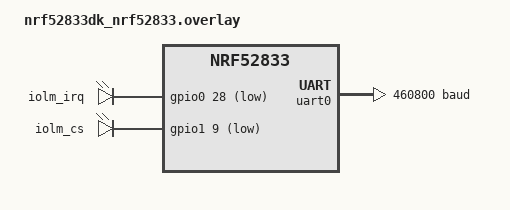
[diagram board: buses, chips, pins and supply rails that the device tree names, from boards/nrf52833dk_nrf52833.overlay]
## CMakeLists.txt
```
# Copyright (c) 2024 Victor Chavez
# SPDX-License-Identifier: GPL-3.0-or-later

cmake_minimum_required(VERSION 3.20.0)
set(IOLINK_MODULE ${CMAKE_CURRENT_SOURCE_DIR}/../..)
set(ZEPHYR_EXTRA_MODULES ${IOLINK_MODULE})
find_package(Zephyr REQUIRED HINTS $ENV{ZEPHYR_BASE})
project(ifm_sample_app)

target_sources(app PRIVATE src/iolink_smi.c
                            src/iolink_handler.c
                            src/iol_master_sample_app.c
)
```

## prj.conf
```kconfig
CONFIG_CPP=y
CONFIG_STD_CPP17=y
CONFIG_THREAD_NAME=y
CONFIG_LOG=y
CONFIG_IOLINK=y
CONFIG_IOLINK_LOG_LEVEL_DBG=y
CONFIG_ASSERT=y
CONFIG_MINIMAL_LIBC=y
CONFIG_MINIMAL_LIBC_MALLOC_ARENA_SIZE=32768
CONFIG_LOG_BUFFER_SIZE=16384
```

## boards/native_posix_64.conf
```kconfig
CONFIG_SPI_EMUL=y
CONFIG_EMUL=y
CONFIG_GPIO_EMUL=y
```

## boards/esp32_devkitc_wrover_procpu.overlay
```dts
/ {

	iolm_gpios: iolm_gpios {
		compatible = "gpio-leds";
		iolm_irq: iolm_irq {
			status = "okay";
			gpios = <&gpio0 18 (GPIO_ACTIVE_LOW)>;
			label = "iolm_irq";
		};
		iolm_cs: iolm_cs {
			status = "okay";
			gpios = <&gpio0 19 (GPIO_ACTIVE_LOW)>;
			label = "iolm_cs";
		};
	};
    
	aliases {
		iolm-spi= &spi2;
        iolm-cs = &iolm_cs;
        iolm-irq = &iolm_irq;
	};

};

&uart0 {
	current-speed = <460800>;
};
```

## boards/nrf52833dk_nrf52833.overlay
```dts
/ {

	iolm_gpios: iolm_gpios {
		compatible = "gpio-leds";
		iolm_irq: iolm_irq {
			status = "okay";
			gpios = <&gpio0 28 (GPIO_ACTIVE_LOW)>;
			label = "iolm_irq";
		};
		iolm_cs: iolm_cs {
			status = "okay";
			gpios = <&gpio1 9 (GPIO_ACTIVE_LOW)>;
			label = "iolm_cs";
		};
	};
    
	aliases {
		iolm-spi= &spi1;
        iolm-cs = &iolm_cs;
        iolm-irq = &iolm_irq;
	};

};

&uart0 {
	current-speed = <460800>;
};

&pinctrl {

	spi1_default: spi1_default {
		group1 {
			psels = <NRF_PSEL(SPIM_SCK, 0, 31)>,
				<NRF_PSEL(SPIM_MOSI, 0, 30)>,
				<NRF_PSEL(SPIM_MISO, 0,29)>;
		};
	};

	spi1_sleep: spi1_sleep {
		group1 {
			psels = <NRF_PSEL(SPIM_SCK, 0, 31)>,
				<NRF_PSEL(SPIM_MOSI, 0, 30)>,
				<NRF_PSEL(SPIM_MISO, 0, 29)>;
			low-power-enable;
		};
	};
};
```

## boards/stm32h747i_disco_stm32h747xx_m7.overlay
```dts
&gpioe {
    status="okay";
};
```

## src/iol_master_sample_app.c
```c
/*********************************************************************
 *        _       _         _
 *  _ __ | |_  _ | |  __ _ | |__   ___
 * | '__|| __|(_)| | / _` || '_ \ / __|
 * | |   | |_  _ | || (_| || |_) |\__ \
 * |_|    \__|(_)|_| \__,_||_.__/ |___/
 *
 * www.rt-labs.com
 * Copyright 2021 rt-labs AB, Sweden.
 *
 * This software is dual-licensed under GPLv3 and a commercial
 * license. See the file LICENSE.md distributed with this software for
 * full license information.
 ********************************************************************/

#include <stdio.h>
#include "osal.h"
#include "osal_irq.h"
#include "osal_log.h"
#include "iolink.h"
#include "iolink_max14819.h"
#include "iolink_handler.h"
#include <iolm/zephyr.h>

static const struct device *const spi_dev = DEVICE_DT_GET(DT_ALIAS(iolm_spi));
static const struct gpio_dt_spec irq_dev = GPIO_DT_SPEC_GET(DT_ALIAS(iolm_irq), gpios);

#define IOLINK_HANDLER_THREAD_STACK_SIZE (8192)
#define IOLINK_HANDLER_THREAD_PRIO       5
static K_THREAD_STACK_DEFINE(iolm_handler_stack, IOLINK_HANDLER_THREAD_STACK_SIZE); 


#define IOLINK_APP_CHIP0_IRQ      25

#define IOLINK_APP_CHIP0_ADDRESS 0x0

#ifndef IOLINK_APP_CHIP1_ADDRESS
#define IOLINK_APP_CHIP1_ADDRESS 0x0
#endif


static iolink_pl_mode_t mode_ch[] =
{
   iolink_mode_SDCI,
   iolink_mode_INACTIVE,
#ifdef IOLINK_APP_CHIP1_SPI
   iolink_mode_SDCI,
   iolink_mode_INACTIVE,
#endif
};

void main_handler_thread (void * ctx)
{
   const iolink_m_cfg_t * cfg = (const iolink_m_cfg_t *)ctx;
   iolink_handler (*cfg);
}

static iolink_hw_drv_t * main_14819_init(const char* name, const iolink_14819_cfg_t * cfg,
                                          const struct device * gpio_port,int irq_pin)
{
   iolink_hw_drv_t  * drv;
   drv = iolink_14819_init (cfg);
   if (drv == NULL)
   {
      LOG_ERR ("APP: Failed to open SPI %s\n", name);
      return NULL;
   }
   if (_iolink_setup_int_zephyr (gpio_port, irq_pin, iolink_14819_isr, drv) < 0)
   {
      LOG_ERR ("APP: Failed to setup interrupt %s\n", name);
      return NULL;
   }
   return drv;
}

static iolink_m_cfg_t iolink_cfg = {
   .cb_arg                   = NULL,
   .cb_smi                   = NULL,
   .cb_pd                    = NULL,
   /* Not needed, statically set with Kconfig*/
   .master_thread_prio       = 0,
   .master_thread_stack_size = 0,
   .dl_thread_prio           = 0,
   .dl_thread_stack_size     = 0,
};

os_thread_t * iolink_handler_thread;
iolink_hw_drv_t * hw[2];
#define CURR_100MA 0x00
#define CURR_200MA 0x01
#define CURR_300MA 0x02
#define CURR_500MA 0x03
#define DRVRCURRLIM_CLDIS BIT(5)

#define CURR_OFF 0x06

#define CL_CONF(x)  ((x) << CURR_OFF)
static const iolink_14819_cfg_t iol_14819_0_cfg = {
      .chip_address   = IOLINK_APP_CHIP0_ADDRESS,
      .spi_slave_name = spi_dev,
      .CQCfgA         = MAX14819_CQCFG_DRVDIS | MAX14819_CQCFG_SINKSEL(0x2),
      .CQCfgB         = MAX14819_CQCFG_DRVDIS | MAX14819_CQCFG_SINKSEL(0x2),
      .LPCnfgA        = MAX14819_LPCNFG_LPEN,
      .LPCnfgB        = MAX14819_LPCNFG_LPEN,
      .IOStCfgA       = MAX14819_IOSTCFG_DICSINK | MAX14819_IOSTCFG_DIEC3TH,
      .IOStCfgB       = MAX14819_IOSTCFG_DICSINK | MAX14819_IOSTCFG_DIEC3TH,
      .DrvCurrLim     = CL_CONF(CURR_300MA),
      .Clock          = MAX14819_CLOCK_XTALEN | MAX14819_CLOCK_TXTXENDIS,
};

#ifdef IOLINK_APP_CHIP1_SPI

static const iolink_14819_cfg_t iol_14819_1_cfg = {
      .chip_address   = IOLINK_APP_CHIP1_ADDRESS,
      .spi_slave_name = IOLINK_APP_CHIP1_SPI,
      .CQCfgA         = MAX14819_CQCFG_DRVDIS | MAX14819_CQCFG_SINKSEL(0x2),
      .LPCnfgA        = MAX14819_LPCNFG_LPEN,
      .IOStCfgA       = MAX14819_IOSTCFG_DICSINK | MAX14819_IOSTCFG_DIEC3TH,
      .DrvCurrLim     = 0x00,
      .Clock          = MAX14819_CLOCK_XTALEN | MAX14819_CLOCK_TXTXENDIS,
};
#endif

iolink_port_cfg_t port_cfgs[] = {
      {
         .name = "/iolink0/0",
         .mode = &mode_ch[0],
         .arg  = (void*)0,
      },
      {
         .name = "/iolink0/1",
         .mode = &mode_ch[0],
         .arg  = (void*)1,
      },
#ifdef IOLINK_APP_CHIP1_SPI
      {
         .name = "/iolink1/0",
         .mode = &mode_ch[2],
         .drv  = hw[1],
         .arg  = (void*)0,
      },
      {
         .name = "/iolink1/1",
         .mode = &mode_ch[3],
         .drv  = hw[1],
         .arg  = (void*)1,
      },
#endif
   };

int main(void)
{


   LOG_INF("Starting app");
   hw[0] = main_14819_init("/iolink0", &iol_14819_0_cfg, irq_dev.port, irq_dev.pin);
   if (hw[0] == NULL) {
      return 0;
   }
#ifdef IOLINK_APP_CHIP1_SPI
   hw[1] = main_14819_init("/iolink1", &iol_14819_1_cfg, irq_dev.port, irq_dev.pin);
#endif
   port_cfgs[0].drv = hw[0];
   port_cfgs[1].drv = hw[0];


   iolink_cfg.port_cnt  = NELEMENTS (port_cfgs);
   iolink_cfg.port_cfgs = port_cfgs;
   LOG_INF("Total port cfg %d",iolink_cfg.port_cnt);

   k_sleep(K_MSEC(200));


   iolink_handler_thread = os_thread_create (
      "iolink_handler_thread",
      IOLINK_HANDLER_THREAD_PRIO,
      iolm_handler_stack,
      K_THREAD_STACK_SIZEOF(iolm_handler_stack),
      main_handler_thread,
      (void*)&iolink_cfg);
   CC_ASSERT (iolink_handler_thread != NULL);
   return 0;
}
```

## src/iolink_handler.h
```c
/*********************************************************************
 *        _       _         _
 *  _ __ | |_  _ | |  __ _ | |__   ___
 * | '__|| __|(_)| | / _` || '_ \ / __|
 * | |   | |_  _ | || (_| || |_) |\__ \
 * |_|    \__|(_)|_| \__,_||_.__/ |___/
 *
 * www.rt-labs.com
 * Copyright 2021 rt-labs AB, Sweden.
 *
 * This software is dual-licensed under GPLv3 and a commercial
 * license. See the file LICENSE.md distributed with this software for
 * full license information.
 ********************************************************************/

#ifndef IOLINK_HANDLER_H
#define IOLINK_HANDLER_H

#include "sys/osal_sys.h"
#include "iolink.h"

#define MASTER_VENDOR_ID 1171
#define MASTER_ID        123

typedef enum
{
   NONE,
   IFM_LAMP,
   IFM_RFID,
   IFM_SENS,
   IFM_HMI,
   GOLDEN,
   UNKNOWN,
} iolink_device_type_t;

/* Port events for app_port.event */
typedef enum
{
   SMI_READ_CNF          = 0x01,
   SMI_WRITE_CNF         = 0x02,
   SMI_PORTCFG_CNF       = 0x04,
   SMI_PORTSTATUS_CNF    = 0x08,
   SMI_MASTERIDENT_CNF   = 0x10,
   SMI_PARSERV_TO_DS_CNF = 0x20,
   SMI_PDIN_CNF = 0x40
} iolink_app_port_event_t;

typedef enum
{
   IOL_STATE_INACTIVE = 0,
   IOL_STATE_STARTING,
   IOL_STATE_STOPPING,
   IOL_STATE_RUNNING,
   IOL_STATE_WU_RETRY_WAIT_TSD,
} iolink_app_port_state_t;

typedef struct iolink_app_portstatus
{
   iolink_port_status_info_t port_status_info;
   iolink_port_quality_info_t port_quality_info;
   uint8_t revision_id;
   iolink_transmission_rate_t transmission_rate;
   uint8_t master_cycle_time;
   uint16_t vendorid;
   uint32_t deviceid;
} iolink_app_port_status_t;

#define PORT_EVENT_COUNT 10

typedef struct iolink_app_master_ctx iolink_app_master_ctx_t;
typedef struct iolink_app_port_ctx iolink_app_port_ctx_t;

typedef struct iolink_app_port_ctx
{
   iolink_app_master_ctx_t * app_master;
   uint8_t portnumber;
   iolink_device_type_t type;
   os_event_t * event;
   uint8_t allocated;
   iolink_app_port_state_t app_port_state;
   iolink_app_port_status_t status;
   os_mutex_t * status_mtx;
   iolink_smi_errortypes_t errortype;
   uint32_t last_pdin_print;

   struct
   {
      uint8_t count;
      diag_entry_t diag_entry[PORT_EVENT_COUNT];
      iolink_eventcode_t eventcode[PORT_EVENT_COUNT];
   } events;
   os_mutex_t * event_mtx;
   struct
   {
      iolink_port_qualifier_info_t pqi;
      uint8_t data[IOLINK_PD_MAX_SIZE];
      uint8_t data_len;
   } pdin;
   struct
   {
      uint16_t data_len;
   } param_read;
   os_mutex_t * pdout_mtx;
   void (*run_function) (iolink_app_port_ctx_t * app_port);
#ifdef __rtk__
   bool alarm_active;
#endif
} iolink_app_port_ctx_t;

typedef struct iolink_app_master_ctx
{
   iolink_m_t * master;
   iolink_app_port_ctx_t app_port[IOLINK_NUM_PORTS];
   os_event_t * app_event;
   uint16_t vendorid;
   uint32_t masterid;
} iolink_app_master_ctx_t;

extern iolink_app_master_ctx_t iolink_app_master;

void iolink_handler (iolink_m_cfg_t m_cfg);

iolink_smi_errortypes_t wait_for_cnf (
   iolink_app_port_ctx_t * app_port,
   uint32_t mask,
   uint32_t ms);

uint8_t get_port_status (iolink_app_port_ctx_t * app_port);

#endif // IOLINK_HANDLER_H
```

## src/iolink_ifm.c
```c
/*********************************************************************
 *        _       _         _
 *  _ __ | |_  _ | |  __ _ | |__   ___
 * | '__|| __|(_)| | / _` || '_ \ / __|
 * | |   | |_  _ | || (_| || |_) |\__ \
 * |_|    \__|(_)|_| \__,_||_.__/ |___/
 *
 * www.rt-labs.com
 * Copyright 2021 rt-labs AB, Sweden.
 *
 * This software is dual-licensed under GPLv3 and a commercial
 * license. See the file LICENSE.md distributed with this software for
 * full license information.
 ********************************************************************/

#include <stdio.h>
#include <string.h>
#include <strings.h>
#include "osal.h"
#include "osal_log.h"
#include "iolink.h"
#include "iolink_handler.h"
#include "iolink_smi.h"

#define RFID_DATA_SIZE 8

static bool ifmrfid_get_tag_present (uint8_t * data)
{
   return (data[1] & 0x04);
}

static uint8_t ifmrfid_get_error_code (uint8_t * data)
{
   return data[31];
}

static bool is_all_zeroes (uint8_t * data, int length)
{
   int i;

   for (i = 0; i < length; i++)
   {
      if (data[i] != 0)
      {
         return false;
      }
   }

   return true;
}

static void ifmrfid_run (iolink_app_port_ctx_t * app_port)
{
   uint8_t port_index = app_port->portnumber - 1;
   uint8_t pdata[IOLINK_PD_MAX_SIZE];
   static bool tag_is_present[IOLINK_NUM_PORTS] = {false};

   if (do_smi_pdin (app_port, NULL, pdata) != IOLINK_PD_MAX_SIZE)
   {
      LOG_WRN (
         "%s: Failed to get PDIn (RFID port #%u)\n",
         __func__,
         app_port->portnumber);
      return;
   }

   uint8_t error_code = ifmrfid_get_error_code (pdata);
   if (error_code != 0)
   {
      LOG_ERR (
         "%s: Got error code %d (RFID port #%u)\n",
         __func__,
         error_code,
         app_port->portnumber);
      return;
   }

   if (ifmrfid_get_tag_present (pdata))
   {
      if (!tag_is_present[port_index]) // tagPresent transition from 0 to 1
      {
         // check if UID is invalid, i.e. all zeroes (data starts at byte 2)
         if (is_all_zeroes (&pdata[2], RFID_DATA_SIZE))
         {
            LOG_ERR (
               "%s: Got tag_present with UID = 0 (RFID port #%u)\n",
               __func__,
               app_port->portnumber);
            return;
         }

         tag_is_present[port_index] = true;
         char UUID[30];
         char * p = UUID;
         int i;
         for (i = 0; i < RFID_DATA_SIZE; i++)
         {
            p += sprintf (p, "%02X", pdata[2 + i]);
         }
         LOG_INF("Port %u: RFID Tag data: %s\n",
            app_port->portnumber,
            UUID);
      }
   }
   else if (tag_is_present[port_index]) // tagPresent transition from 1 to 0
   {
      tag_is_present[port_index] = false;
      LOG_INF ("Port %u: RFID Tag not present\n",
         app_port->portnumber);
   }
}

void ifmrfid_setup (iolink_app_port_ctx_t * app_port)
{
   uint8_t data[2] = {0, 0};

   LOG_INF ("Set up RFID on port %u\n", app_port->portnumber);

   // Blocksize 4
   data[0] = 4;
   if (do_smi_device_write (app_port, 1900, 0, 1, data) != IOLINK_ERROR_NONE)
   {
      LOG_ERR (
         "Set up RFID blocksize failed on port %u\n",
         app_port->portnumber);
      return;
   }

   // Data order normal
   data[0] = 0;
   if (do_smi_device_write (app_port, 1901, 0, 1, data) != IOLINK_ERROR_NONE)
   {
      LOG_ERR (
         "Set up RFID data order failed on port %u\n",
         app_port->portnumber);
      return;
   }

   // Data hold time
   data[0] = 0;
   data[1] = 50;
   if (do_smi_device_write (app_port, 1902, 0, 2, data) != IOLINK_ERROR_NONE)
   {
      LOG_ERR (
         "Set up RFID data hold failed on port %u\n",
         app_port->portnumber);
      return;
   }

   // Auto read/write length
   data[0] = 4;
   if (do_smi_device_write (app_port, 1904, 0, 1, data) != IOLINK_ERROR_NONE)
   {
      LOG_ERR (
         "Set up RFID auto read/write failed on port %u\n",
         app_port->portnumber);
      return;
   }

   app_port->type = IFM_RFID;

   app_port->run_function = ifmrfid_run;

   app_port->app_port_state = IOL_STATE_RUNNING;
}

// ifmMHI Process data offsets
#define VALUE_LINE_1_MSB 0
#define VALUE_LINE_1_LSB 1
#define VALUE_LINE_2_MSB 2
#define VALUE_LINE_2_LSB 3
#define COLOR_LINE_1     8
#define COLOR_LINE_2     9
#define LEDS             12
#define LAYOUT           13

// ifmMHI Process data values
#define DOWN_KEY_PRESSED  BIT (0)
#define UP_KEY_PRESSED    BIT (1)
#define ENTER_KEY_PRESSED BIT (2)
#define ESC_KEY_PRESSED   BIT (3)
#define BLACK_WHITE       0
#define RED               1
#define GREEN             2
#define YELLOW            3
#define BLINK             40
#define DISPLAY_TEXT      80
#define LED_1_ON          BIT (0)
#define LED_1_OFF         0
#define LED_2_ON          BIT (2)
#define LED_2_OFF         0
#define ONE_LINE          1
#define TWO_LINES         2
#define TEXT_ID(n)        (n)

#define IFM_MHI_PD_SIZE 16

static void ifmHMI_run (iolink_app_port_ctx_t * app_port)
{
   static uint32_t itr          = 0;
   static uint8_t prev_hmi_pdin = 0;
   static uint8_t hmi_pdin      = 0;
   bool pdin_valid              = false;

   itr++;

   if ((itr % 100) == 0)
   {
      static uint8_t addr     = 0;
      static uint8_t data[12] = {
         'A',
         ' ',
         ' ',
         ' ',
         ' ',
         ' ',
         ' ',
         ' ',
         ' ',
         ' ',
         ' ',
         ' ',
      };
      static uint8_t i = 0;

      /* 90 or 91, description of line 1 and 2 */
      uint16_t index = 90 + (addr % 2);

      if (do_smi_device_write (app_port, index, 0, sizeof (data), data) != IOLINK_ERROR_NONE)
      {
         LOG_WRN (
            
            "%s: Failed to write on port %u\n",
            __func__,
            app_port->portnumber);
      }

      if (data[i] == 'Z')
      {
         i++;
         i       = i % 12;
         data[i] = 'A';
      }
      else
      {
         data[i]++;
      }
      addr++;
   }

   if (do_smi_pdin (app_port, &pdin_valid, &hmi_pdin) != sizeof (hmi_pdin) != IOLINK_ERROR_NONE)
   {
      LOG_WRN (
         
         "%s: Failed to get PDIn from port %u\n",
         __func__,
         app_port->portnumber);
   }
   else
   {
      if (!pdin_valid)
      {
         LOG_WRN (
            
            "%s: PDIn data is invalid for port %u\n",
            __func__,
            app_port->portnumber);
      }
      else
      {
         if (prev_hmi_pdin != hmi_pdin)
         {
            LOG_INF (
               
               "\nUp: %u\nDown: %u\nEnter: %u\nEsc: %u\n\n",
               hmi_pdin & UP_KEY_PRESSED ? 1 : 0,
               hmi_pdin & DOWN_KEY_PRESSED ? 1 : 0,
               hmi_pdin & ENTER_KEY_PRESSED ? 1 : 0,
               hmi_pdin & ESC_KEY_PRESSED ? 1 : 0);
            prev_hmi_pdin = hmi_pdin;
         }
      }
   }

   if ((itr % 512) == 0)
   {
      static bool show_text = false;

      uint8_t data[IFM_MHI_PD_SIZE];
      bzero (data, sizeof (data));

      if (show_text)
      {
         data[VALUE_LINE_1_LSB] = TEXT_ID (4);
         data[COLOR_LINE_1]     = YELLOW | DISPLAY_TEXT;
         data[LEDS]             = LED_1_OFF | LED_2_ON;
         data[LAYOUT]           = ONE_LINE;
      }
      else
      {
         uint32_t val           = itr - 512;
         data[VALUE_LINE_1_MSB] = val >> 8;
         data[VALUE_LINE_1_LSB] = val;
         data[VALUE_LINE_2_MSB] = val >> 18;
         data[VALUE_LINE_2_LSB] = val >> 10;
         data[COLOR_LINE_1]     = GREEN;
         data[COLOR_LINE_2]     = RED | BLINK;
         data[LEDS]             = LED_1_ON | LED_2_OFF;
         data[LAYOUT]           = TWO_LINES;
      }

      do_smi_pdout (app_port, true, sizeof (data), data);
      show_text = !show_text;
   }

   if ((itr % 2048) == 0)
   {
      if (do_smi_device_read (app_port, 90, 0, 17, NULL, NULL) != IOLINK_ERROR_NONE)
      {
         LOG_WRN (
            
            "%s: Failed to read from port %u\n",
            __func__,
            app_port->portnumber);
      }
   }

   if ((itr % 8192) == 0)
   {
      if (do_smi_pdinout (app_port) != IOLINK_ERROR_NONE)
      {
         LOG_WRN (
            
            "%s: PDInOut failed on port %u\n",
            __func__,
            app_port->portnumber);
      }
   }
}

void ifmHMI_setup (iolink_app_port_ctx_t * app_port)
{
   uint8_t data[IFM_MHI_PD_SIZE];
   bzero (data, sizeof (data));

   LOG_INF ( "Set up HMI on port %u\n", app_port->portnumber);

   data[VALUE_LINE_1_LSB] = TEXT_ID (3);
   data[COLOR_LINE_1]     = BLACK_WHITE | DISPLAY_TEXT;
   data[LEDS]             = LED_1_ON | LED_2_OFF;
   data[LAYOUT]           = TWO_LINES;

   do_smi_pdout (app_port, true, sizeof (data), data);

   app_port->type = IFM_HMI;

   app_port->run_function = ifmHMI_run;

   app_port->app_port_state = IOL_STATE_RUNNING;
}
```

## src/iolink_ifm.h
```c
/*********************************************************************
 *        _       _         _
 *  _ __ | |_  _ | |  __ _ | |__   ___
 * | '__|| __|(_)| | / _` || '_ \ / __|
 * | |   | |_  _ | || (_| || |_) |\__ \
 * |_|    \__|(_)|_| \__,_||_.__/ |___/
 *
 * www.rt-labs.com
 * Copyright 2021 rt-labs AB, Sweden.
 *
 * This software is dual-licensed under GPLv3 and a commercial
 * license. See the file LICENSE.md distributed with this software for
 * full license information.
 ********************************************************************/

#ifndef IOLINK_IFM_H
#define IOLINK_IFM_H

#include "iolink_handler.h"

#define IFM_VENDOR_ID 0x0136

#define IFM_RFID_DEVICE_ID 0x03C7
#define IFM_HMI_DEVICE_ID  0x02A9

void ifmrfid_setup (iolink_app_port_ctx_t * app_port);

void ifmHMI_setup (iolink_app_port_ctx_t * app_port);

#endif // IOLINK_IFM_H
```

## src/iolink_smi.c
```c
/*********************************************************************
 *        _       _         _
 *  _ __ | |_  _ | |  __ _ | |__   ___
 * | '__|| __|(_)| | / _` || '_ \ / __|
 * | |   | |_  _ | || (_| || |_) |\__ \
 * |_|    \__|(_)|_| \__,_||_.__/ |___/
 *
 * www.rt-labs.com
 * Copyright 2021 rt-labs AB, Sweden.
 *
 * This software is dual-licensed under GPLv3 and a commercial
 * license. See the file LICENSE.md distributed with this software for
 * full license information.
 ********************************************************************/

#include <string.h>
#include "osal.h"
#include "osal_log.h"
#include "iolink.h"
#include "iolink_main.h"
#include "iolink_dl.h"
#include "iolink_handler.h"

iolink_smi_errortypes_t do_smi_device_write (
   iolink_app_port_ctx_t * app_port,
   uint16_t index,
   uint8_t subindex,
   uint8_t len,
   const uint8_t * data)
{
   uint8_t arg_block_len = sizeof (arg_block_od_t) + len;
   uint8_t buffer[arg_block_len];
   arg_block_od_t * arg_block_od = (arg_block_od_t *)buffer;

   memset (buffer, 0, arg_block_len);
   arg_block_od->arg_block.id = IOLINK_ARG_BLOCK_ID_OD_WR;
   arg_block_od->index        = index;
   arg_block_od->subindex     = subindex;

   memcpy (arg_block_od->data, data, len);

   iolink_error_t err = SMI_DeviceWrite_req (
      app_port->portnumber,
      IOLINK_ARG_BLOCK_ID_VOID_BLOCK,
      arg_block_len,
      (arg_block_t *)arg_block_od);
   if (err != IOLINK_ERROR_NONE)
   {
      LOG_WARNING (
         LOG_STATE_ON,
         "%s failed (SMI_DeviceWrite_req returned %d) for port %u\n",
         __func__,
         err,
         app_port->portnumber);

      return (err == IOLINK_ERROR_ODLENGTH)
                ? IOLINK_SMI_ERRORTYPE_VAL_LENOVRRUN
                : IOLINK_SMI_ERRORTYPE_APP_DEV; // TODO
   }

   return wait_for_cnf (app_port, SMI_WRITE_CNF, 10000);
}

iolink_smi_errortypes_t do_smi_device_read (
   iolink_app_port_ctx_t * app_port,
   uint16_t index,
   uint8_t subindex,
   uint8_t len,
   uint8_t * data,
   uint8_t * actual_len)
{
   if (len == 0)
   {
      LOG_WARNING (
         LOG_STATE_ON,
         "%s: len == 0 for port %u\n",
         __func__,
         app_port->portnumber);

      return IOLINK_SMI_ERRORTYPE_ARGBLOCK_INCONSISTENT; // TODO what to return?
   }

   uint16_t arg_block_len = sizeof (arg_block_od_t) + len;
   uint8_t buffer[arg_block_len];
   arg_block_od_t * arg_block_od = (arg_block_od_t *)buffer;

   memset (buffer, 0, arg_block_len);
   arg_block_od->arg_block.id = IOLINK_ARG_BLOCK_ID_OD_RD;
   arg_block_od->index        = index;
   arg_block_od->subindex     = subindex;

   iolink_smi_errortypes_t errortype = IOLINK_SMI_ERRORTYPE_NONE;
   iolink_error_t err                = SMI_DeviceRead_req (
      app_port->portnumber,
      IOLINK_ARG_BLOCK_ID_OD_RD,
      arg_block_len,
      (arg_block_t *)arg_block_od);
   if (err != IOLINK_ERROR_NONE)
   {
      LOG_WARNING (
         LOG_STATE_ON,
         "%s failed (SMI_DeviceRead_req returned %d) for port %u\n",
         __func__,
         err,
         app_port->portnumber);

      errortype = IOLINK_SMI_ERRORTYPE_APP_DEV; // TODO
   }
   else
   {
      uint32_t event_value;

      /* Wait for SMI_DeviceRead_cnf() */
      if (os_event_wait (app_port->event, SMI_READ_CNF, &event_value, 10000))
      {
         errortype = app_port->errortype;

         LOG_WARNING (
            LOG_STATE_ON,
            "%s: timeout for port %u\n",
            __func__,
            app_port->portnumber);

         if (errortype != IOLINK_SMI_ERRORTYPE_NONE)
         {
            app_port->errortype = IOLINK_SMI_ERRORTYPE_NONE;
         }
         else
         {
            errortype = IOLINK_SMI_ERRORTYPE_APP_DEV; // TODO
         }
      }
      else
      {
         os_event_clr (app_port->event, event_value);

         if (data != NULL)
         {
            if (app_port->param_read.data_len > 0)
            {
               memcpy (data, arg_block_od->data, len);

               if (actual_len != NULL)
               {
                  *actual_len = app_port->param_read.data_len;
               }
            }

            app_port->param_read.data_len = 0;
         }
      }
   }

   return errortype;
}

uint8_t do_smi_pdout (
   iolink_app_port_ctx_t * app_port,
   bool output_enable,
   uint8_t len,
   const uint8_t * data)
{
   os_mutex_lock (app_port->pdout_mtx);

   arg_block_pdout_t arg_block_pdout;

   arg_block_pdout.h.arg_block.id = IOLINK_ARG_BLOCK_ID_PD_OUT;
   memcpy (arg_block_pdout.data, data, len);
   arg_block_pdout.h.len = len;
   arg_block_pdout.h.oe  = (output_enable) ? 1 : 0;

   iolink_error_t err = SMI_PDOut_req (
      app_port->portnumber,
      IOLINK_ARG_BLOCK_ID_VOID_BLOCK,
      sizeof (arg_block_pdout_head_t) + len,
      (arg_block_t *)&arg_block_pdout);
   os_mutex_unlock (app_port->pdout_mtx);

   return (err == IOLINK_ERROR_NONE) ? 0 : 1;
}

int8_t do_smi_pdin (iolink_app_port_ctx_t * app_port, bool * valid)
{
   arg_block_void_t arg_block_void;
   int8_t len = 0;

   memset (&arg_block_void, 0, sizeof (arg_block_void_t));
   arg_block_void.arg_block.id = IOLINK_ARG_BLOCK_ID_VOID_BLOCK;

   return SMI_PDIn_req (
         app_port->portnumber,
         IOLINK_ARG_BLOCK_ID_PD_IN,
         sizeof (arg_block_void_t),
         (arg_block_t *)&arg_block_void) == IOLINK_ERROR_NONE? 0:-1;
}

uint8_t do_smi_pdinout (iolink_app_port_ctx_t * app_port)
{
   arg_block_void_t arg_block_void;

   memset (&arg_block_void, 0, sizeof (arg_block_void_t));
   arg_block_void.arg_block.id = IOLINK_ARG_BLOCK_ID_VOID_BLOCK;

   iolink_error_t err = SMI_PDInOut_req (
      app_port->portnumber,
      IOLINK_ARG_BLOCK_ID_PD_IN_OUT,
      sizeof (arg_block_void_t),
      (arg_block_t *)&arg_block_void);

   return (err == IOLINK_ERROR_NONE) ? 0 : 1;
}
```

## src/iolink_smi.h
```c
/*********************************************************************
 *        _       _         _
 *  _ __ | |_  _ | |  __ _ | |__   ___
 * | '__|| __|(_)| | / _` || '_ \ / __|
 * | |   | |_  _ | || (_| || |_) |\__ \
 * |_|    \__|(_)|_| \__,_||_.__/ |___/
 *
 * www.rt-labs.com
 * Copyright 2021 rt-labs AB, Sweden.
 *
 * This software is dual-licensed under GPLv3 and a commercial
 * license. See the file LICENSE.md distributed with this software for
 * full license information.
 ********************************************************************/

#ifndef IOLINK_SMI_H
#define IOLINK_SMI_H

#include "iolink.h"
#include "iolink_handler.h"

iolink_smi_errortypes_t do_smi_device_write (
   iolink_app_port_ctx_t * app_port,
   uint16_t index,
   uint8_t subindex,
   uint8_t len,
   const uint8_t * data);

iolink_smi_errortypes_t do_smi_device_read (
   iolink_app_port_ctx_t * app_port,
   uint16_t index,
   uint8_t subindex,
   uint8_t len,
   uint8_t * data,
   uint8_t * actual_len);

uint8_t do_smi_pdout (
   iolink_app_port_ctx_t * app_port,
   bool output_enable,
   uint8_t len,
   const uint8_t * data);

int8_t do_smi_pdin (iolink_app_port_ctx_t * app_port, bool * valid);

uint8_t do_smi_pdinout (iolink_app_port_ctx_t * app_port);

#endif // IOLINK_SMI_H
```
